# RL7005_IP_SVD register map
Vendor: Realtek
Registers are 32-bit, read-write, reset 0x0 unless marked. A register's access mark holds for its fields unless they carry their own. Offsets are from the block's base; [hi:lo] are bit positions; {n}, {i} and the like mark numbered series.

## IWDG_REG
Base 0x4080AC00
Same registers: WDG0_REG 0x4080AD00, WDG2_REG 0x4080AD80, WDG1_REG_S 0x5080AD40
0x00 WDG_MKEYR — WDG Magic Key register
  [15:0] MKEY — 0x6969: enable access to register WDG_CR/WDG_RLR/WDG_WINR 0x5A5A: reload WDG counter 0x3C3C: enable WDG function
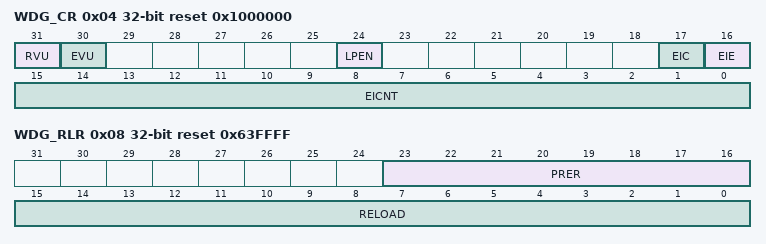
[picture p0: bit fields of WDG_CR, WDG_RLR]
0x04 WDG_CR access per field reset 0x1000000 — WDG Control regsietr
  [31] RVU ro — Watchdog counter update by reload command
  [30] EVU ro — Watchdog early interrupt function update
  [24] LPEN rw — Low power enable 0: WDG will gating when system goes into sleep mode 1: WDG keep running when system goes into sleep mode
  [17] EIC wo — Write '1' clear the early interrupt
  [16] EIE rw — Watchdog early interrupt enable
  [15:0] EICNT rw — Early interrupt trigger threshold
0x08 WDG_RLR reset 0x63FFFF — WDG Relaod register
  [23:16] PRER — Prescaler counter, configuration only allowed before wdg enable WDG: 0x63 System wdg: 0x1F
  [15:0] RELOAD — Reload value for watchdog counter Default : 64s (@100k)
0x0C WDG_WINR reset 0xFFFF — WDG Window Register
  [15:0] WINDOW — Watchdog feed protect window register
0x10 IWDG_DUMMY reset 0xFF — Wdg Dummy Register
  [15:0] dummy — rsvd for hw

## PAGE26
Base 0x40000000
0x2600 TWT_BC_ID — TWT IE ID BITMAP
  [31:0] r_BC_TWT_ID — TWT ID bitmap, each bit corresponding to a ID value
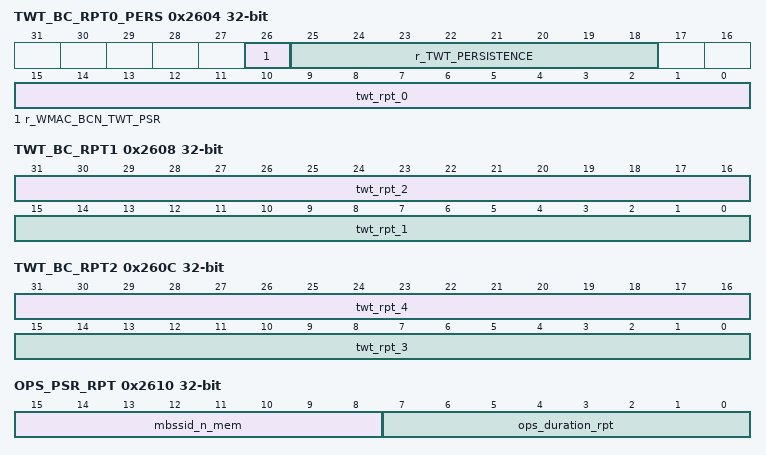
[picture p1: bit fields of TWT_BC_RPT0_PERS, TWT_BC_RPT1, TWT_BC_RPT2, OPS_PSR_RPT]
0x2604 TWT_BC_RPT0_PERS — TWT IE persistence reference and RPT0
  [26] r_WMAC_BCN_TWT_PSR — enable bcn twt bc ie parser
  [25:18] r_TWT_PERSISTENCE — persistence vlaue, if persistence value in TWT IE is smaller than the reference, bcnpsf will lat the twt id rpt
  [15:0] twt_rpt_0 — specified twt id report
0x2608 TWT_BC_RPT1 — TWT IE ID RPT1
  [31:16] twt_rpt_2 — specified twt id report
  [15:0] twt_rpt_1 — specified twt id report
0x260C TWT_BC_RPT2 — TWT IE ID RPT2
  [31:16] twt_rpt_4 — specified twt id report
  [15:0] twt_rpt_3 — specified twt id report
0x2610 OPS_PSR_RPT — OPS DURATION
  [15:8] mbssid_n_mem — multi-bssid n value
  [7:0] ops_duration_rpt — ops frame duration field rpt
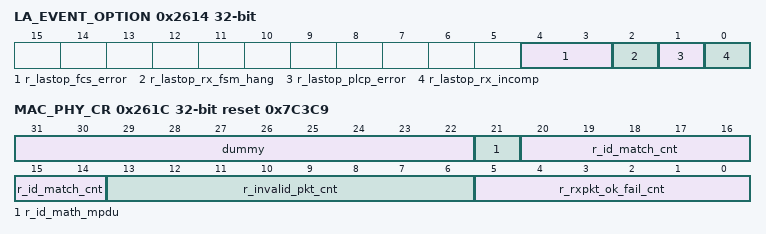
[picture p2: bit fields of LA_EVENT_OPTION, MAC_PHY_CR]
0x2614 LA_EVENT_OPTION
  [4:3] r_lastop_fcs_error — stop LA record when continue fcs error >= threshold 0:disable 1:4 2:8 3:12
  [2] r_lastop_rx_fsm_hang — stop LA record when RX FSM timeout
  [1] r_lastop_plcp_error — stop LA record when RX PLCP error occur, include Length error, parity error or crc error
  [0] r_lastop_rx_incomp — stop LA record when RX content is incompleted, include PLCP is incompleted or PSDU is incompleted
0x2618 RESP_AID_11 — aid 11 for resp
  [10:0] aid11 — specified the aid of the sta that mactx responding to
0x261C MAC_PHY_CR reset 0x7C3C9 — mac phy control reg
  [31:22] dummy
  [21] r_id_math_mpdu — when set, per mpdu will trigger rx_id_match, else per ppdu trigger rx_id_match
  [20:14] r_id_match_cnt — rxpkt_ok or rxpkt_fail pulse counter,unit 25ns when mac clock is 40MHz
  [13:6] r_invalid_pkt_cnt — invalid_pkt pulse counter,unit 25ns when mac clock is 40MHz
  [5:0] r_rxpkt_ok_fail_cnt — rxpkt_ok or rxpkt_fail pulse counter,unit 25ns when mac clock is 40MHz

## MAC_SRAM
Base 0x40000000
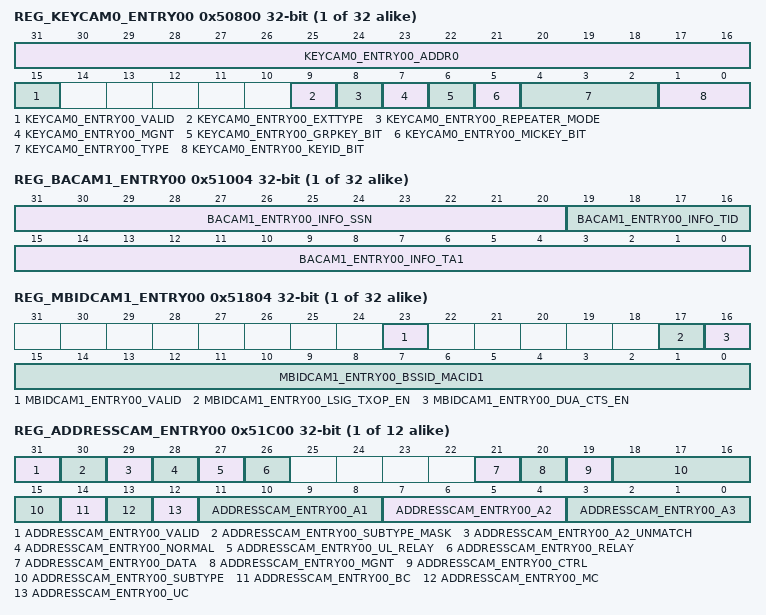
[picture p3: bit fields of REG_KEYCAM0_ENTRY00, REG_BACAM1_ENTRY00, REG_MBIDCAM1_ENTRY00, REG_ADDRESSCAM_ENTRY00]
{0x50800+0x20*i} REG_KEYCAM0_ENTRY{i:02} (i=0..31)
  [31:16] KEYCAM0_ENTRY{i:02}_ADDR0 — address[15:0]
  [15] KEYCAM0_ENTRY{i:02}_VALID
  [9] KEYCAM0_ENTRY{i:02}_EXTTYPE
  [8] KEYCAM0_ENTRY{i:02}_REPEATER_MODE
  [7] KEYCAM0_ENTRY{i:02}_MGNT
  [6] KEYCAM0_ENTRY{i:02}_GRPKEY_BIT
  [5] KEYCAM0_ENTRY{i:02}_MICKEY_BIT
  [4:2] KEYCAM0_ENTRY{i:02}_TYPE
  [1:0] KEYCAM0_ENTRY{i:02}_KEYID_BIT
{0x50804+0x20*i} REG_KEYCAM1_ENTRY{i:02} (i=0..31)
  [31:0] KEYCAM1_ENTRY{i:02}_ADDR1 — address[47:16]
{0x50808+0x20*i} REG_KEYCAM2_ENTRY{i:02} (i=0..31)
  [31:0] KEYCAM2_ENTRY{i:02}_KEY0 — key[31:0]
{0x5080C+0x20*i} REG_KEYCAM3_ENTRY{i:02} (i=0..31)
  [31:0] KEYCAM3_ENTRY{i:02}_KEY1 — key[63:32]
{0x50810+0x20*i} REG_KEYCAM4_ENTRY{i:02} (i=0..31)
  [31:0] KEYCAM4_ENTRY{i:02}_KEY2 — key[95:64]
{0x50814+0x20*i} REG_KEYCAM5_ENTRY{i:02} (i=0..31)
  [31:0] KEYCAM5_ENTRY{i:02}_KEY3 — key[127:96]
{0x50818+0x20*i} REG_KEYCAM6_ENTRY{i:02} (i=0..31)
  [31:25] KEYCAM6_ENTRY{i:02}_MFB
{0x51000+0x10*i} REG_BACAM0_ENTRY{i:02} (i=0..31)
  [31:0] BACAM0_ENTRY{i:02}_INFO_TA0
{0x51004+0x10*i} REG_BACAM1_ENTRY{i:02} (i=0..31)
  [31:20] BACAM1_ENTRY{i:02}_INFO_SSN, [19:16] BACAM1_ENTRY{i:02}_INFO_TID, [15:0] BACAM1_ENTRY{i:02}_INFO_TA1
{0x51008+0x10*i} REG_BACAM2_ENTRY{i:02} (i=0..31)
  [31:0] BACAM2_ENTRY{i:02}_BITMAP0
{0x5100C+0x10*i} REG_BACAM3_ENTRY{i:02} (i=0..31)
  [31:0] BACAM3_ENTRY{i:02}_BITMAP1
{0x51800+8i} REG_MBIDCAM0_ENTRY{i:02} (i=0..31)
  [31:0] MBIDCAM0_ENTRY{i:02}_BSSID_MACID0
{0x51804+8i} REG_MBIDCAM1_ENTRY{i:02} (i=0..31)
  [23] MBIDCAM1_ENTRY{i:02}_VALID
  [17] MBIDCAM1_ENTRY{i:02}_LSIG_TXOP_EN — only use in mbidcam
  [16] MBIDCAM1_ENTRY{i:02}_DUA_CTS_EN — only use in mbidcam
  [15:0] MBIDCAM1_ENTRY{i:02}_BSSID_MACID1
0x51900 REG_DUMMY
{0x51C00+4i} REG_ADDRESSCAM_ENTRY{i:02} (i=0..11)
  [31] ADDRESSCAM_ENTRY{i:02}_VALID, [30] ADDRESSCAM_ENTRY{i:02}_SUBTYPE_MASK, [29] ADDRESSCAM_ENTRY{i:02}_A2_UNMATCH, [28] ADDRESSCAM_ENTRY{i:02}_NORMAL, [27] ADDRESSCAM_ENTRY{i:02}_UL_RELAY, [26] ADDRESSCAM_ENTRY{i:02}_RELAY, [21] ADDRESSCAM_ENTRY{i:02}_DATA, [20] ADDRESSCAM_ENTRY{i:02}_MGNT, [19] ADDRESSCAM_ENTRY{i:02}_CTRL, [18:15] ADDRESSCAM_ENTRY{i:02}_SUBTYPE, [14] ADDRESSCAM_ENTRY{i:02}_BC, [13] ADDRESSCAM_ENTRY{i:02}_MC, [12] ADDRESSCAM_ENTRY{i:02}_UC, [11:8] ADDRESSCAM_ENTRY{i:02}_A1, [7:4] ADDRESSCAM_ENTRY{i:02}_A2, [3:0] ADDRESSCAM_ENTRY{i:02}_A3

## SHA_KEY_REG
Base 0x40814000
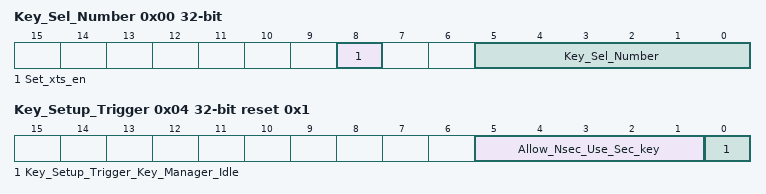
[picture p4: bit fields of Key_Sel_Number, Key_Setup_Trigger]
0x00 Key_Sel_Number — Key Selection Number Register
  [8] Set_xts_en — Only available when SUPPORT_XTS_MODE = 1. When this bit is set to 1, the trigger will write the selected key to xts_key2. Otherwise, the trigger will write the selected key to key/xts_key1.
  [5:0] Key_Sel_Number — The key number determines which key to use in the key setting. HW keys: 0~31, the number can be used is determined by the number of HW keys configured. Hardwired key: 32, if enabled Secure SW key: 33 Shared SW key: 34~ , the number can be used is determined by the number of SW keys configured.
0x04 Key_Setup_Trigger access per field reset 0x1 — Key Setup Process Trigger Register
  [5:1] Allow_Nsec_Use_Sec_key ro — When setting this field to 1, allow non-secure domain to trigger the secure key. Only secure domain can write this bit. The corresponding bits will be numbered from smallest to largest. For example, the number of the secure domain key is 0, 1, 33. Bits 0, 1, 2 control key0, key1, key33 respectively.
  [0] Key_Setup_Trigger_Key_Manager_Idle rw — Write 1 to trigger key setup process If the selected key is a hardware key, assert hw_key_req and wait for hw_key_ack. The key setup process will not start until hw_key_ack is received. The key managment unit uses the APB interface to pass the key into the engine according to the selected key. The read data represents whether the engine is idle or not. 0: Key setup process ongoing 1: Key setup is completed After triggering the key setup process, read this bit to confirm completion.
0x10 Secure_key0_7 — Secure key0 Register[255:224]
  [31:0] Secure_Key0_7 — Secure key0 register[32*7+31:31*7]
0x14 Secure_key0_6 — Secure key0 Register[223:192]
  [31:0] Secure_Key0_6 — Secure key0 register[32*6+31:31*6]
0x18 Secure_key0_5 — Secure key0 Register[191:160]
  [31:0] Secure_Key0_5 — Secure key0 register[32*5+31:31*5]
0x1C Secure_key0_4 — Secure key0 Register[159:128]
  [31:0] Secure_Key0_4 — Secure key0 register[32*4+31:31*4]
0x20 Secure_key0_3 — Secure key0 Register[127:96]
  [31:0] Secure_Key0_3 — Secure key0 register[32*3+31:31*3]
0x24 Secure_key0_2 — Secure key0 Register[95:64]
  [31:0] Secure_Key0_2 — Secure key0 register[32*2+31:31*2]
0x28 Secure_key0_1 — Secure key0 Register[63:32]
  [31:0] Secure_Key0_1 — Secure key0 register[32*1+31:31*1]
0x2C Secure_key0_0 — Secure key0 Register[31:0]
  [31:0] Secure_Key0_0 — Secure key0 register[32*0+31:31*0]
0x30 Shared_key0_7 — Shared key0 Register[255:224]
  [31:0] Shared_Key0_7 — Shared key0 register[32*7+31:32*7]
0x34 Shared_key0_6 — Shared key0 Register[223:192]
  [31:0] Shared_Key0_6 — Shared key0 register[32*6+31:32*6]
0x38 Shared_key0_5 — Shared key0 Register[191:160]
  [31:0] Shared_Key0_5 — Shared key0 register[32*5+31:32*5]
0x3C Shared_key0_4 — Shared key0 Register[159:128]
  [31:0] Shared_Key0_4 — Shared key0 register[32*4+31:32*4]
0x40 Shared_key0_3 — Shared key0 Register[127:96]
  [31:0] Shared_Key0_3 — Shared key0 register[32*3+31:32*3]
0x48 Shared_key0_2 — Shared key0 Register[95:64]
  [31:0] Shared_Key0_2 — Shared key0 register[32*2+31:32*2]
0x48 Shared_key0_1 — Shared key0 Register[63:32]
  [31:0] Shared_Key0_1 — Shared key0 register[32*1+31:32*1]
0x4C Shared_key0_0 — Shared key0 Register[31:0]
  [31:0] Shared_Key0_0 — Shared key0 register[32*0+31:32*0]
